# nrf7140_wificore register map
Vendor: Nordic Semiconductor; Series: nRF71; File version: 1
Registers are 32-bit, read-write, reset 0x0 unless marked. A register's access mark holds for its fields unless they carry their own. Offsets are from the block's base; [hi:lo] are bit positions; lines under a group give offsets from that group; {n}, {i} and the like mark numbered series.

## RPUPHY (part 3 of 8) — WIFICore RPU PHY peripherals
Base 0x48080000; alternate view of RPUMAC
0x8000 WLAN_CTRL group — Unspecified
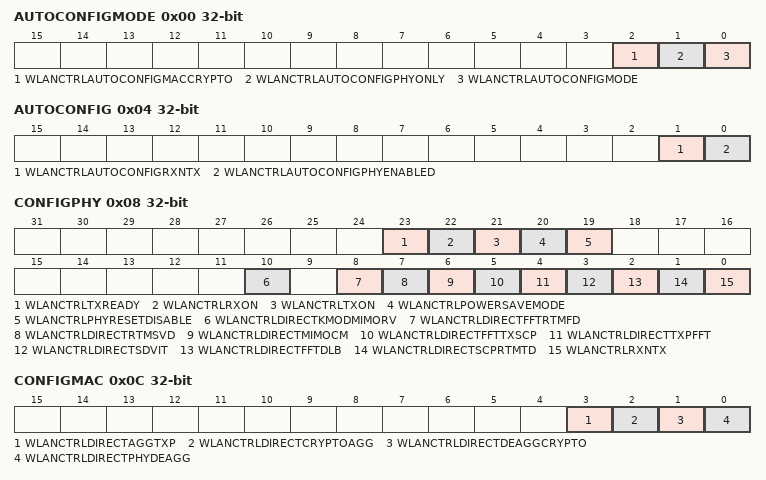
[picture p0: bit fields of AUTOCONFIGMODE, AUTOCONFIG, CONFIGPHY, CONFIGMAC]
  0x00 AUTOCONFIGMODE — WLAN CTRL AUTO CONFIG MODE
    [2] WLANCTRLAUTOCONFIGMACCRYPTO — Enable auto-configuration MAC with or without Crypto
      0=Auto-configure MAC pipeline with Crypto; 1=AutoConfigureMacPip1 (Auto-configure MAC pipeline without Crypto)
    [1] WLANCTRLAUTOCONFIGPHYONLY — Enable auto-configuration for PHY+MAC or PHY-only
      0=Auto-configure full PHY+MAC pipeline; 1=Auto-configure only PHY pipeline
    [0] WLANCTRLAUTOCONFIGMODE — Select mode used for automatic configuration:
      0=Automatic PHY configuration through WLAN_CTRL_AUTO_CONFIG register; 1=AutomaticPhyConfigur1 (Automatic PHY configuration using direct lines from MAC controller)
  0x04 AUTOCONFIG — WLAN CTRL AUTO CONFIG
    [1] WLANCTRLAUTOCONFIGRXNTX — Configure Wi-Fi RX or TX mode:
      0=Tx; 1=Rx
    [0] WLANCTRLAUTOCONFIGPHYENABLED — Enable PHY for either RX or TX:
      0=PhyDisabled; 1=PhyEnabled
  0x08 CONFIGPHY — WLAN CTRL CONFIG PHY
    [23] WLANCTRLTXREADY — Enable TX-SCP output:
      0=Disabled; 1=Enabled
    [22] WLANCTRLRXON — Set RF RX on:
      0=RxOff; 1=RxOn
    [21] WLANCTRLTXON — Set RF TX on:
      0=TxOff; 1=TxOn
    [20] WLANCTRLPOWERSAVEMODE — Enable Power Save mode:
      0=Disabled; 1=Enabled
    [19] WLANCTRLPHYRESETDISABLE — Control for automatic PHY reset (RX mode):
      0=PHY reset will be automatically generated; 1=No automatic PHY reset is generated
    [10] WLANCTRLDIRECTKMODMIMORV — Select whether MIMO RV input is from DMA channels or a direct connection between peripherals:
      0=DmaChannels; 1=Direct connection between peripherals
    [8] WLANCTRLDIRECTFFTRTMFD — Select whether FFT data input to RTM FD are from DMA channels or a direct connection from FFT:
      0=DmaChannels; 1=Direct connection between peripherals
    [7] WLANCTRLDIRECTRTMSVD — Select whether WLAN SVD input is from DMA channels or a direct connection between peripherals:
      0=DmaChannels; 1=Direct connection between peripherals
    [6] WLANCTRLDIRECTMIMOCM — Select whether MIMO Channel Matrix input is from DMA channels or a direct connection between peripherals:
      0=DmaChannels; 1=Direct connection between peripherals
    [5] WLANCTRLDIRECTFFTTXSCP — Select whether FFT output and TX-SCP input are to/from DMA channels or a direct connection between peripherals:
      0=DmaChannels; 1=Direct connection between peripherals
    [4] WLANCTRLDIRECTTXPFFT — Select whether TXP output and FFT input are to/from DMA channels or a direct connection between peripherals:
      0=DmaChannels; 1=Direct connection between peripherals
    [3] WLANCTRLDIRECTSDVIT — Select whether Stream Deparser outputs and Viterbi Decoder inputs are to/from DMA channels or a direct connection between peripherals:
      0=DmaChannels; 1=Direct connection between peripherals
    [2] WLANCTRLDIRECTFFTDLB — Select whether FFT output and DLB input are to/from DMA channels or a direct connection between peripherals:
      0=DmaChannels; 1=Direct connection between peripherals
    [1] WLANCTRLDIRECTSCPRTMTD — Select whether SCP outputs and RTM_TD input are to/from DMA channels or a direct connection between peripherals:
      0=DmaChannels; 1=Direct connection between peripherals
    [0] WLANCTRLRXNTX — Configure Wi-Fi RX or TX mode:
      0=Tx; 1=Rx
  0x0C CONFIGMAC — WLAN CTRL CONFIG MAC
    [all] fields
      0=DmaChannels; 1=Direct connection between peripherals
    [3] WLANCTRLDIRECTAGGTXP — Select whether Aggregation output and TXP input are to/from DMA channels or a direct connection between peripherals:
    [2] WLANCTRLDIRECTCRYPTOAGG — Select whether Crypto output and Aggregation input are to/from DMA channels or a direct connection between peripherals:
    [1] WLANCTRLDIRECTDEAGGCRYPTO — Select whether Deaggregation output and Crypto input are to/from DMA channels or a direct connection between peripherals:
    [0] WLANCTRLDIRECTPHYDEAGG — Select whether PHY outputs and Deaggregation inputs are to/from DMA channels or a direct connection between peripherals:
  0x10 TXHOLDOFF — WLAN CTRL TX HOLDOFF
    [13:0] WLANCTRLTXHOLDOFF — Specify TX hold-off to delay TX output to the DAC.Units are core clock cycles.
  0x14 TXEXTRAHOLDOFF — WLAN CTRL TX EXTRA HOLDOFF
    [13:0] WLANCTRLTXEXTRAHOLDOFF — Specify extra TX hold-off to delay TX output to the DAC.This extra hold-off can be selected through the TX vector.Units are core clock cycles.
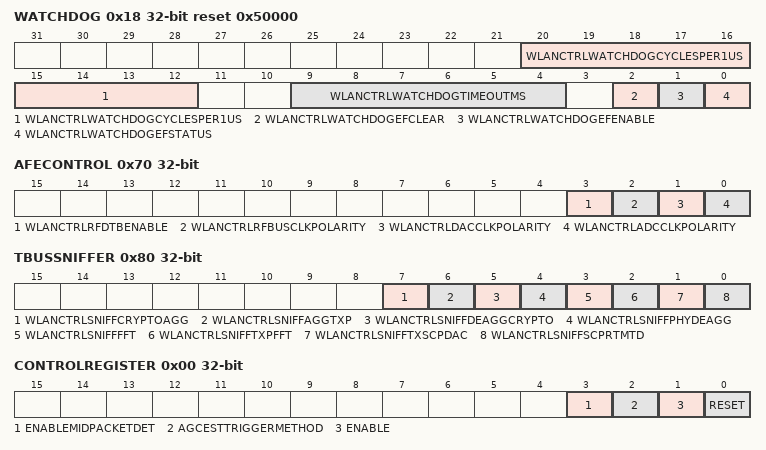
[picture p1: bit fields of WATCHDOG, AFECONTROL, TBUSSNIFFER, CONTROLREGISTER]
  0x18 WATCHDOG reset 0x50000 — WLAN CTRL WATCHDOG
    [20:12] WLANCTRLWATCHDOGCYCLESPER1US — Configure the number of core clock cycles per microsecond.
    [9:4] WLANCTRLWATCHDOGTIMEOUTMS — Specify watchdog timeout in milliseconds. Zero means the watchdog event flag is disabled.
    [2] WLANCTRLWATCHDOGEFCLEAR — WLAN watchdog event flag acknowledge/clear.Write 1 to clear WLAN_CTRL_WATCHDOG_EF_STATUS.Writing 0 has no effect.
    [1] WLANCTRLWATCHDOGEFENABLE — WLAN watchdog event flag enable.ANDed with WLAN_CTRL_WATCHDOG_EF_STATUS before generating EF output from block.
    [0] WLANCTRLWATCHDOGEFSTATUS — WLAN watchdog event flag status.Latched high when watchdog timer reaches programmed thresholdCan be forced high by writing 1 to this register for debug purposes (to test event flag connectivity in hardware and software).
  0x1C DEBUGPHYRESET ro — WLAN CTRL DEBUG PHY RESET
    [5:0] WLANCTRLDEBUGPHYRESET — Live state of the PHY reset signals0: PHY reset1: EDAGC reset2: SCP reset3: TD reset4: FD reset5: RXP reset
  0x20 DEBUGGING — WLAN CTRL DEBUG
    [1:0] WLANCTRLDEBUG — Enable debug registers PHY_VALID, PHY_ENABLE, MAC_VALID and MAC_ENABLE
      0=Disabled; 1=ValidEnable; 2=Sticky(Valid), Sticky(Enable); 3=Valid & Enable, Sticky(Valid & Enable)
  0x24 DEBUGPHYVALID ro — WLAN CTRL DEBUG PHY VALID
    [10:0] WLANCTRLDEBUGPHYVALID — Live state of the PHY valid flow control signals0: TXFD Input1: TXFD Output2: RXTD Input3: RXTD OFDM Output4: RXTD DSSS Output5: FFT Input6: FFT Output7: TXTD Input8: TXTD Output9: RXFD FFT Input10: RXFD Output
  0x28 DEBUGPHYENABLE ro — WLAN CTRL DEBUG PHY ENABLE
    [10:0] WLANCTRLDEBUGPHYENABLE — Live state of the PHY enable flow control signals0: TXFD Input1: TXFD Output2: RXTD Input3: RXTD OFDM Output4: RXTD DSSS Output5: FFT Input6: FFT Output7: TXTD Input8: TXTD Output9: RXFD FFT Input10: RXFD Output
  0x2C DEBUGMACVALID ro — WLAN CTRL DEBUG MAC VALID
    [6:0] WLANCTRLDEBUGMACVALID — Live state of the MAC valid flow control signals0: AGG WR1: AGG RD2: DEAGG WR3: DEAGG RD4: CRYPTO WR5: CRYPTO RD6: DECOMP WR
  0x30 DEBUGMACENABLE ro — WLAN CTRL DEBUG MAC ENABLE
    [6:0] WLANCTRLDEBUGMACENABLE — Live state of the MAC enable flow control signals0: AGG WR1: AGG RD2: DEAGG WR3: DEAGG RD4: CRYPTO WR5: CRYPTO RD6: DECOMP WR
  0x34 CCABUSYCOUNT0 — WLAN CTRL CCA BUSY COUNT 0
    [0] WLANCTRLCCABUSYCOUNTENA — Enable / disable CCA busy window counter. When disabled counter is set to zero.
  0x38 CCABUSYCOUNT1 ro — WLAN CTRL CCA BUSY COUNT 1
    [23:0] WLANCTRLCCABUSYCOUNTER — CCA busy window counter in Core clock cycles.
  0x3C NUMPAYLOADBYTESFORDEASSERTION — WLAN CTRL NUM PAYLOAD BYTES FOR DEASSERTION
    [5:0] WLANCTRLNUMPAYLOADBYTESFORDEASSERTION — Number of payload bytes after which PHY_RX_Request is deasserted.This value is set such that PHY-RX-Request is asserted till MAC hardware checkswhether MAC address of receiving packet is matching with expected address,i.e., this number should cover more than 10 bytes of MPDU.Typical value is 20 considering A-MPDU and some margin for MAC address matching.
  0x40 TMCOUNTERMSB — WLAN CTRL TM COUNTER MSB
    [23:0] WLANCTRLTMCOUNTERMSB — MSB of Counter used for time measurement snapshots
  0x44 TMCOUNTERLSB — WLAN CTRL TM COUNTER LSB
    [23:0] WLANCTRLTMCOUNTERLSB — LSB of Counter used for time measurement snapshots
  0x48 ADCFIRSTSAMPLESNAPSHOTMSB ro — WLAN CTRL ADC FIRST SAMPLE SNAPSHOT MSB
    [23:0] WLANCTRLADCFIRSTSAMPLESNAPSHOTMSB — MSB of snapshot of time measurement counter, taken when first sample of ADC goes valid
  0x4C ADCFIRSTSAMPLESNAPSHOTLSB ro — WLAN CTRL ADC FIRST SAMPLE SNAPSHOT LSB
    [23:0] WLANCTRLADCFIRSTSAMPLESNAPSHOTLSB — LSB of snapshot of time measurement counter, taken when first sample of ADC goes valid
  0x50 TMCOUNTERCTRL — WLAN CTRL TM COUNTER CTRL
    [0] WLANCTRLTMCOUNTERENABLE — Enable signal for 48-bit time measurement counter
  0x54 TXABORTCONTROL — WLAN CTRL TX ABORT CONTROL
    [0] WLANCTRLTXABORTCONTROL — Control to assert wlan_ctrl_rx_on when TX_ABORT is received.
      0=Do not assert wlan_ctrl_rx_on; 1=Assert wlan_ctrl_rx_on when abort_status is high
  0x58 OFDMRTMSCPEOPSNAPSHOTMSB ro — WLAN CTRL OFDM RTM SCP EOP SNAPSHOT MSB
    [23:0] WLANCTRLOFDMRTMSCPEOPSNAPSHOTMSB — MSB of snapshot of time measurement counter, taken when OFDM Receiver Training Mode - SCP EOP goes high
  0x5C OFDMRTMSCPEOPSNAPSHOTLSB ro — WLAN CTRL OFDM RTM SCP EOP SNAPSHOT LSB
    [23:0] WLANCTRLOFDMRTMSCPEOPSNAPSHOTLSB — LSB of snapshot of time measurement counter, taken when OFDM Receiver Training Mode - SCP EOP goes high
  0x60 OFDMRTMFDEOPSNAPSHOTMSB ro — WLAN CTRL OFDM RTM FD EOP SNAPSHOT MSB
    [23:0] WLANCTRLOFDMRTMFDEOPSNAPSHOTMSB — MSB of snapshot of time measurement counter, taken when OFDM Receiver Training Mode - FD EOP goes high
  0x64 OFDMRTMFDEOPSNAPSHOTLSB ro — WLAN CTRL OFDM RTM FD EOP SNAPSHOT LSB
    [23:0] WLANCTRLOFDMRTMFDEOPSNAPSHOTLSB — LSB of snapshot of time measurement counter, taken when OFDM Receiver Training Mode - FD EOP goes high
  0x68 TMCOUNTERSNAPSHOTMSB — WLAN CTRL TM COUNTER SNAPSHOT MSB
    [23:0] WLANCTRLTMCOUNTERSNAPSHOTMSB — MSB of snapshot of time measurement counter, taken when either WLAN_CTRL_TM_COUNTER_SNAPSHOT_MSB or WLAN_CTRL_TM_COUNTER_SNAPSHOT_LSB is written
  0x6C TMCOUNTERSNAPSHOTLSB — WLAN CTRL TM COUNTER SNAPSHOT LSB
    [23:0] WLANCTRLTMCOUNTERSNAPSHOTLSB — LSB of snapshot of time measurement counter, taken when either WLAN_CTRL_TM_COUNTER_SNAPSHOT_MSB or WLAN_CTRL_TM_COUNTER_SNAPSHOT_LSB is written
  0x70 AFECONTROL — WLAN CTRL AFE CONTROL
    [3] WLANCTRLRFDTBENABLE — RF Digital Test Bus enable
      0=RfDtbNotEnabled; 1=RfDrbEnabled
    [2] WLANCTRLRFBUSCLKPOLARITY — RF bus clock polarity:
      0=PositiveEdge; 1=NegativeEdge
    [1] WLANCTRLDACCLKPOLARITY — DAC sample clock polarity:
      0=PositiveEdge; 1=NegativeEdge
    [0] WLANCTRLADCCLKPOLARITY — ADC sample clock polarity:
      0=PositiveEdge; 1=NegativeEdge
  0x74 RFPMUUP — WLAN CTRL RF PMU UP
    [0] WLANCTRLRFPMUUP — Enable RF:
      0=Not enabled (PMU_UP_P=0 and PMU_UP_N=1); 1=Enabled (PMU_UP_P=1 and PMU_UP_N=0)
  0x78 RFBANDSEL — WLAN CTRL RF BAND SEL
    [0] WLANCTRLRFBANDSEL — Select between low band and high band RF:
      0=LowBand; 1=HighBand
  0x80 TBUSSNIFFER — WLAN CTRL TBUS SNIFFER
    [all] fields
      0=NotSniffed; 1=Sniff Tbus connection whilst in direct connection
    [7] WLANCTRLSNIFFCRYPTOAGG — Select whether Crypto outputs and Agg input are output to the EDC during direct connection:
    [6] WLANCTRLSNIFFAGGTXP — Select whether AGG outputs and TXP input are output to the EDC during direct connection:
    [5] WLANCTRLSNIFFDEAGGCRYPTO — Select whether DEAGG outputs and CRYPTO input are output to the EDC during direct connection:
    [4] WLANCTRLSNIFFPHYDEAGG — Select whether PHY outputs and DEAGG input are output to the EDC during direct connection:
    [3] WLANCTRLSNIFFFFT — Select whether FFT outputs and MIMO/TXSCP input are output to the EDC during direct connection:
    [2] WLANCTRLSNIFFTXPFFT — Select whether TXP outputs and FFT input are output to the EDC during direct connection:
    [1] WLANCTRLSNIFFTXSCPDAC — Select whether TX-SCP outputs and DAC input are output to the EDC during direct connection:
    [0] WLANCTRLSNIFFSCPRTMTD — Select whether SCP outputs and RTM_TD input are output to the EDC during direct connection:
  0xFC WLANCOREREVISION ro
    [23:0] WLANCOREREVISION — WiFi Core revision : Major(8).Minor(8).Maintenance(8)
0x9000 WLAN_ED group — Unspecified
  0x00 CONTROLREGISTER — WLAN ED CONTROL REGISTER
    [3] ENABLEMIDPACKETDET — When set Mid-Packet detection is enabled; otherwise only DSSS and OFDM packets will be detected.
    [2] AGCESTTRIGGERMETHOD — Defines the AGC trigger method.'0' -Agc estimation process starts only after ED done'1' -Agc is free running and starts adjusting gain value if absolute difference in RSSI and target value is more than threshold.
    [1] ENABLE — 1: Enables ED module0: Disables ED module
    [0] RESET — 1: Asserts reset0: De-asserts reset
  0x04 WAITCOUNTER — WLAN ED WAIT COUNTER
    [7:0] WAITCOUNT — Number of data samples for which module waits before it actually starts processing.
  0x08 THRESHSETTINGS — WLAN ED THRESH SETTINGS
    [7:0] EDTHRESHOLD — RSSI Threshold in dBm corresponding to sensitivity required. Signal crossing this threshold indicates energy in the channel.
  0x0C ESTIMATIONLENGTH — WLAN ED ESTIMATION LENGTH
    [1:0] ESTIMATIONLENGTH — No of symbols to be averaged to Estimate Average variance.0: 1 symbol, 1: 2 symbols, 2: 4 symbols, 3: 8 symbols
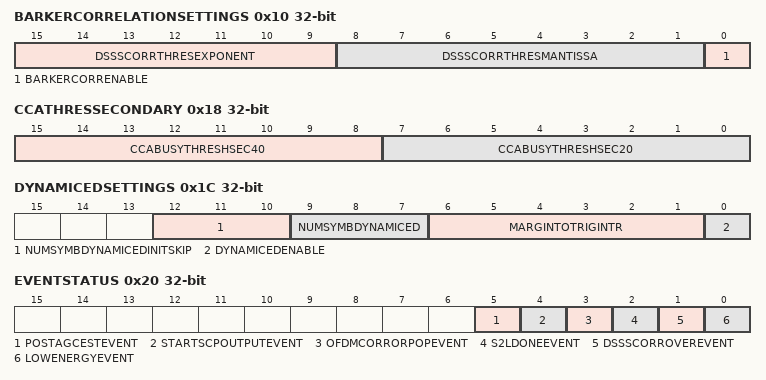
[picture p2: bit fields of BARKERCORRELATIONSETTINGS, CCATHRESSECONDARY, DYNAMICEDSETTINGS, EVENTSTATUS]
  0x10 BARKERCORRELATIONSETTINGS — WLAN ED BARKER CORRELATION SETTINGS
    [15:9] DSSSCORRTHRESEXPONENT — DSSS Correlation Threshold:Represents 8 bit Exponent value of Threshold.
    [8:1] DSSSCORRTHRESMANTISSA — DSSS Correlation Threshold:Represents 8 bit Mantissa value of Threshold.
    [0] BARKERCORRENABLE — 1: Enables Barker correlationThis correlation is performed on data stream-1.
  0x14 CCATHRESPRIM20 — WLAN ED CCA THRES PRIM20
    [7:0] CCABUSYTHRESHPRIM20 — Signal level in dB corresponding to CCA threshold in the primary 20MHz channel. The threshold is given in 2's complement form.
  0x18 CCATHRESSECONDARY — WLAN ED CCA THRES SECONDARY
    [15:8] CCABUSYTHRESHSEC40 — Signal level in dB corresponding to CCA threshold in the secondary 40MHz channel. The threshold is given in 2's complement form.
    [7:0] CCABUSYTHRESHSEC20 — Signal level in dB corresponding to CCA threshold in the secondary 20MHz channel. The threshold is given in 2's complement form.
  0x1C DYNAMICEDSETTINGS — WLAN ED DYNAMIC ED SETTINGS
    [12:10] NUMSYMBDYNAMICEDINITSKIP — This specifies the number of consecutive below-threshold events to skip, before starting the count for low energy event. Can take values from 0 to 7. Suppose the value is 3 then it skips first 3 consecutive below-threshold symbols, then proceeds to count for generating low energy event. If the below-threshold events are not consecutive then the count is reset.
    [9:7] NUMSYMBDYNAMICED — Number of Symbols to determine Average Energy. Valid only when Dynamic ED is enabled.0: 1 symbol, 1: 2 symbols, 2: 4 symbols, 3: 8 symbols, 4:16 symbols, 5: 32 symbols, 6: 64 symbols, 7: 128 symbols
    [6:1] MARGINTOTRIGINTR — If the energy found over all the NUM_SYMB_DYNAMIC_ED symbols is consistently below the ED threshold an interrupt is generated. Field is valid only when dynamic ED is enabled. 0: 0dB, 1: 1dB, 2: 2 dB15: 15 dB.
    [0] DYNAMICEDENABLE — 1-Enable, 0-Disable
  0x20 EVENTSTATUS ro — WLAN ED EVENT STATUS
    [5] POSTAGCESTEVENT — This event register holds the status of the post AGC estimations being valid.'1' - Event detected.'0' - Event not detected.
    [4] STARTSCPOUTPUTEVENT — This event register holds the status of the SCP output and indicates when the SCP output was set valid.'1' - Event detected.'0' - Event not detected.
    [3] OFDMCORRORPOPEVENT — This event status register holds the status of post AGC OFDM correlation completion if AGC_EST_TRIGGER_METHOD is 0 or packet over packet detection event if AGC_EST_TRIGGER_METHOD is 1.'1' - Event detected.'0' - Event not detected.
    [2] S2LDONEEVENT — '1' - S2L processing is over.'0' - S2L processing is not over.
    [1] DSSSCORROVEREVENT — This field will be set once the correlation is done over desired number of symbols after assertion of AGC done signal.
    [0] LOWENERGYEVENT — 1: Event status. Asserted when energy is below a threshold by a margin
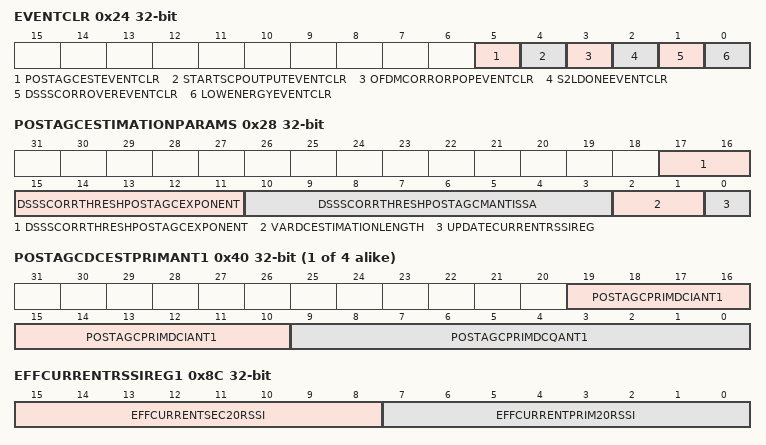
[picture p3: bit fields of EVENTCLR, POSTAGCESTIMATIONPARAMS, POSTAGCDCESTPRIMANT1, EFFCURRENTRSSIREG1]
  0x24 EVENTCLR — WLAN ED EVENT CLR
    [5] POSTAGCESTEVENTCLR — This event clear register resets the status of the post AGC estimations.
    [4] STARTSCPOUTPUTEVENTCLR — This event clear register resets the status of the SCP output event.
    [3] OFDMCORRORPOPEVENTCLR — This event clear register resets the status of post AGC OFDM correlation completion or packet over packet detection event.
    [2] S2LDONEEVENTCLR — Clears the S2L done Event.
    [1] DSSSCORROVEREVENTCLR — Clears DSSS correlation event
    [0] LOWENERGYEVENTCLR — Clears low energy event
  0x28 POSTAGCESTIMATIONPARAMS — WLAN ED POST AGC ESTIMATION PARAMS
    [17:11] DSSSCORRTHRESHPOSTAGCEXPONENT — DSSS Correlation Threshold:Represents 8 bit Exponent value of Threshold.
    [10:3] DSSSCORRTHRESHPOSTAGCMANTISSA — DSSS Correlation Threshold:Represents 8 bit Mantissa value of Threshold.
    [2:1] VARDCESTIMATIONLENGTH — Number of symbol over which variance is computed after AGC estimation.0: 1 symbol1: 2 symbols2: 4 symbols3: 8 symbolsEach symbol constitutes number of samples defined in estimation length (ESTIMATION_LENGTH_1)
    [0] UPDATECURRENTRSSIREG — Flag to Enable or Disable, update of RSSI register values with Current Symbol RSSI
  {0x14+0x18*j} POSTAGCVARIANCEESTPRIM80ANT{j} ro (j=1..4) — WLAN ED POSTAGC VARIANCE EST PRIM80 ANT{j}
    [19:0] POSTAGCPRIM80VARANT{j} — Post AGC variance average of primary 80MHz channel for antenna {j}
  {0x18+0x18*j} POSTAGCVARIANCEESTPRIM40ANT{j} ro (j=1..4) — WLAN ED POSTAGC VARIANCE EST PRIM40 ANT{j}
    [19:0] POSTAGCPRIM40VARANT{j} — Post AGC variance average of primary 40MHz channel for antenna {j}
  {0x1C+0x18*j} POSTAGCVARIANCEESTPRIM20ANT{j} ro (j=1..4) — WLAN ED POSTAGC VARIANCE EST PRIM20 ANT{j}
    [19:0] POSTAGCPRIM20VARANT{j} — Post AGC variance average of primary 20MHz channel for antenna {j}
  {0x20+0x18*j} POSTAGCVARIANCEESTSEC40ANT{j} ro (j=1..4) — WLAN ED POSTAGC VARIANCE EST SEC40 ANT{j}
    [19:0] POSTAGCSEC40VARANT{j} — Post AGC variance average of secondary 40MHz channel for antenna {j}
  {0x24+0x18*j} POSTAGCVARIANCEESTSEC20ANT{j} ro (j=1..4) — WLAN ED POSTAGC VARIANCE EST SEC20 ANT{j}
    [19:0] POSTAGCSEC20VARANT{j} — Post AGC variance average of secondary 20MHz channel for antenna {j}
  {0x28+0x18*j} POSTAGCDCESTPRIMANT{j} ro (j=1..4) — WLAN ED POSTAGC DCEST PRIM ANT{j}
    [19:10] POSTAGCPRIMDCIANT{j} — DC offset of I component of primary input stream after AGC estimation is completed for antenna {j}. If RX_OPER_FS is:00 then primary input implies primary 20MHz channel01 then primary input implies primary 40MHz channel10 then primary input implies primary 80MHz channel
    [9:0] POSTAGCPRIMDCQANT{j} — DC offset of Q component of primary input stream after AGC estimation is completed for antenna {j}. If RX_OPER_FS is:00 then primary input implies primary 20MHz channel01 then primary input implies primary 40MHz channel10 then primary input implies primary 80MHz channel
  0x8C EFFCURRENTRSSIREG1 ro — WLAN ED EFF CURRENT RSSI REG1
    [15:8] EFFCURRENTSEC20RSSI — Effective current symbol secondary 20MHz RSSI
    [7:0] EFFCURRENTPRIM20RSSI — Effective current symbol primary 20MHz RSSI.
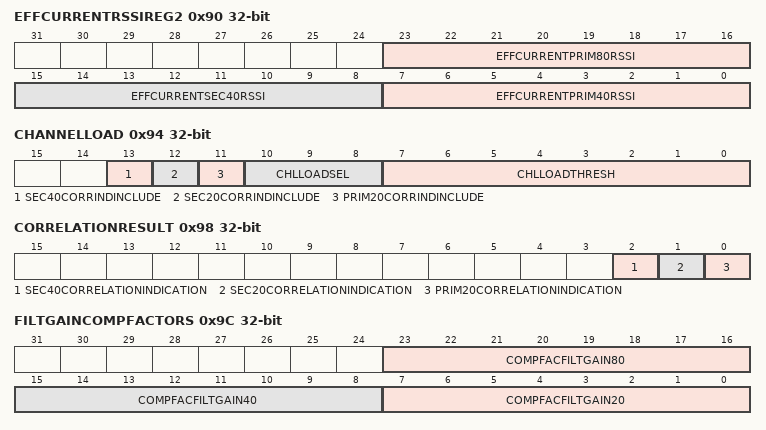
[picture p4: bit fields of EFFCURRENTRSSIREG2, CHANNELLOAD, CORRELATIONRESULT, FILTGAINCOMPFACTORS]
  0x90 EFFCURRENTRSSIREG2 ro — WLAN ED EFF CURRENT RSSI REG2
    [23:16] EFFCURRENTPRIM80RSSI — Effective current symbol primary 80MHz RSSI.
    [15:8] EFFCURRENTSEC40RSSI — Effective current symbol secondary 40MHz RSSI.
    [7:0] EFFCURRENTPRIM40RSSI — Effective current symbol primary 40MHz RSSI.
  0x94 CHANNELLOAD — WLAN ED CHANNEL LOAD
    [13] SEC40CORRINDINCLUDE — If this is set secondary40 correlation result in included in providing channel load information.
    [12] SEC20CORRINDINCLUDE — If this is set secondary20 correlation result in included in providing channel load information.
    [11] PRIM20CORRINDINCLUDE — If this is set primary correlation result in included in providing channel load information.
    [10:8] CHLLOADSEL — 012
    [7:0] CHLLOADTHRESH — A signal is asserted whenever received signal in primary channel crossing this threshold . Threshold value is configured in steps of 1dB ranging from -128dB to 127dB.
  0x98 CORRELATIONRESULT — WLAN ED CORRELATION RESULT
    [2] SEC40CORRELATIONINDICATION — This signal logical 'OR'ed with CCA busy of secondary 40MHz channel indicates channel busy condition. This can be cleared once PLCP header is successfully received.MCP sets this bit if it sees correlation successful in secondary 40MHz channel.
    [1] SEC20CORRELATIONINDICATION — This signal logical 'OR'ed with CCA busy of secondary 20MHz channel indicates channel busy condition. This can be cleared once PLCP header is successfully received.MCP sets this bit if it sees correlation successful in secondary channel.
    [0] PRIM20CORRELATIONINDICATION — This signal logical 'OR'ed with CCA busy of primary 20MHz channel indicates channel busy condition. This can be cleared once PLCP header is successfully received. MCP sets this bit if it sees correlation successful in secondary channel.
  0x9C FILTGAINCOMPFACTORS — WLAN ED FILT GAIN COMP FACTORS
    [23:16] COMPFACFILTGAIN80 — This is gain difference between two filters.Value = 20**log10(2^(N_ADC_BITS-1)/ADC_PK_VOLT) + (FILT1_GAIN - FILT2_GAIN)N_ADC_BITS : Number of ADC bits (10)ADC_PK_VOLT : ADC peak voltage level (0.5V)FILT_GAIN: Gain in dB due to filter
    [15:8] COMPFACFILTGAIN40 — Value = 20**log10(2^(N_ADC_BITS-1)/ADC_PK_VOLT) + FILT_GAINN_ADC_BITS : Number of ADC bits (10)ADC_PK_VOLT : ADC peak voltage level (0.5V)FILT_GAIN: Gain in dB due to filter
    [7:0] COMPFACFILTGAIN20 — Value = 20**log10(2^(N_ADC_BITS-1)/ADC_PK_VOLT) + FILT_GAINN_ADC_BITS : Number of ADC bits (10)ADC_PK_VOLT : ADC peak voltage level (0.5V)FILT_GAIN: Gain in dB due to filter
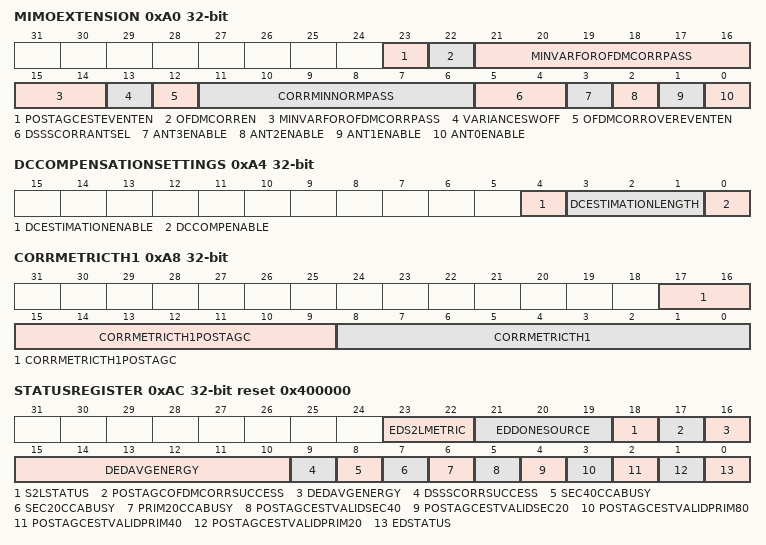
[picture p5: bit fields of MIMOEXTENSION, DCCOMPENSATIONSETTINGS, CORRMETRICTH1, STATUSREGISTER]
  0xA0 MIMOEXTENSION — WLAN ED MIMO EXTENSION
    [23] POSTAGCESTEVENTEN — This register enables the assertion of post AGC estimation event.'0' - Event assertion is disabled.'1' - Event assertion is enabled.
    [22] OFDMCORREN — OFDM correlation enable.'1' - OFDM correlation enabled.'0' - OFDM correlation disabled.
    [21:14] MINVARFOROFDMCORRPASS — This register holds the minimum value of RSSI in dBm (signed), that is necessary for OFDM correlation check to pass. If the computed RSSI is below thisvalue then even though OFDM correlation metric is high the OFDM correlation success will not be enabled, so ED will not be successful. This is used for preventing low amplitude periodic signals especially DC offset from triggering OFDM correlation based ED.
    [13] VARIANCESWOFF — Bit to switch off the variance computation modules inside ed module.'1' - switch off the variance estimation modules.'0' - don't switch off. Controlled according to internal logic.
    [12] OFDMCORROVEREVENTEN — This register enable the assertion of OFDM post AGC correlation done event.'0' - Event assertion is disabled.'1' - Enabled.
    [11:6] CORRMINNORMPASS — Denotes the number of passes for the correlation metric above threshold for Correlation Pass in ED.
    [5:4] DSSSCORRANTSEL — The antenna index to be selected for DSSS correlation in ED. Can be from 0 to 3.
    [3] ANT3ENABLE — Enables Antenna 3 input processing in ED module
    [2] ANT2ENABLE — Enables Antenna 2 input processing in ED module
    [1] ANT1ENABLE — Enables Antenna 1 input processing in ED module
    [0] ANT0ENABLE — Enables Antenna 0 input processing for ED module.
  0xA4 DCCOMPENSATIONSETTINGS — WLAN ED DC COMPENSATION SETTINGS
    [4] DCESTIMATIONENABLE
    [3:1] DCESTIMATIONLENGTH — DC Estimation Length indicates the number of samples over which DC should be estimated in the signal preprocessor block.'000' - 8 Samples'001' - 16 Samples'010' - 32 Samples'011' - 64 Samples'100' - 128 Samples
    [0] DCCOMPENABLE — 1->Enable DC compensation0->Disable DC compensation
  0xA8 CORRMETRICTH1 — WLAN ED CORR METRIC TH1
    [17:9] CORRMETRICTH1POSTAGC — Post AGC CorrMetric Threshold.Contains two's complement representation of corr metric threshold , in dB with 3 bit precision after decimal point. i.e. upto 0.125dB accuracy. For example, 332 indicates -22.5dB threshold. 257 indicates -31.875dB threshold.
    [8:0] CORRMETRICTH1 — Contains two's complement representation of corr metric threshold , in dB with 3 bit precision after decimal point. i.e. upto 0.125dB accuracy. For example, 332 indicates -22.5dB threshold. 257 indicates -31.875dB threshold.
  0xAC STATUSREGISTER ro reset 0x400000 — WLAN ED STATUS REGISTER
    [23:22] EDS2LMETRIC — This register indicates the metric of s2l done event.
    [21:19] EDDONESOURCE — This register indicates the source of ED done event.'001' - ED due to prim20 variance exceeding threshold.'010' - ED due to prim20 OFDM correlation exceeding threshold.'011' - ED due to prim20 DSSS correlation exceeding threshold.'100' - ED due to prim20 RSSI between ED detection and CCA'101' - ED due to sec20 RSSI between ED detection and CCA'110' - ED due to sec40 RSSI between ED detection and CCAThe value in this register is only valid when ED_STATUS=1.When ED_STATUS=0 the value in this register is only for debug purposes.
    [18] S2LSTATUS — '1' - S2L Detected.'0' - S2L TimeOut.
    [17] POSTAGCOFDMCORRSUCCESS — This bit gives the post AGC OFDM correlation status.'0' - Correlation Failure.'1' - Correlation success.
    [16:10] DEDAVGENERGY — This is the estimate of average energy in dB (10**log10(var)) when dynamic ed event occured
    [9] DSSSCORRSUCCESS — Value of '1' indicates DSSS correlation is successful.
    [8] SEC40CCABUSY — Level 'High' indicates secondary channel is busy.
    [7] SEC20CCABUSY — Secondary 20MHz CCA Busy Signal.
    [6] PRIM20CCABUSY — Primary20MHz CCA Busy Signal
    [5] POSTAGCESTVALIDSEC40 — Value '1' indicates post AGC estimation performed over sec40 signal are valid.
    [4] POSTAGCESTVALIDSEC20 — Value '1' indicates post AGC estimation performed over sec20 signal are valid.
    [3] POSTAGCESTVALIDPRIM80 — Value '1' indicates post AGC estimation performed over prim80 signal are valid.
    [2] POSTAGCESTVALIDPRIM40 — Value '1' indicates post AGC estimation performed over prim40 signal are valid.
    [1] POSTAGCESTVALIDPRIM20 — Value '1' indicates post AGC estimation performed over prim20 signal are valid.
    [0] EDSTATUS — Level 'High' indicates energy is detected.
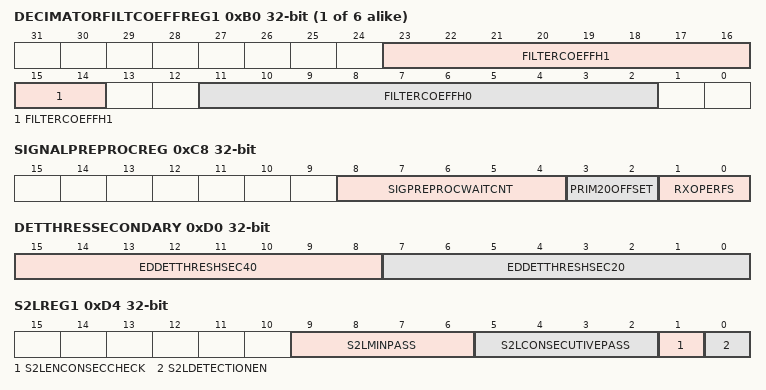
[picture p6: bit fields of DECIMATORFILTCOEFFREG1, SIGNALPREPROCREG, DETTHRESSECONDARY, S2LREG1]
  {0xAC+4j} DECIMATORFILTCOEFFREG{j} (j=1..6) — WLAN ED DECIMATOR FILT COEFF REG{j}
    [23:14] FILTERCOEFFH{2j-1} — Decimator filter tap {2j-1} coefficients. Expressed in 10-bit 2's complement
    [11:2] FILTERCOEFFH{2j-2} — Decimator filter tap {2j-2} coefficients. Expressed in 10-bit 2's complement
  0xC8 SIGNALPREPROCREG — WLAN ED SIGNAL PREPROC REG
    [8:4] SIGPREPROCWAITCNT — This is a 5-bit value specifies how many valid scp output samples to wait before enabling the signal preprocessor
    [3:2] PRIM20OFFSET — This indicates the offset of the primary20MHz.if RX_OPER_FS = '00' (20MHz)'00' - This is the only allowed value.if RX_OPER_FS = '01' (40MHz)'00' - Primary 20 is the lower 20 MHz.'01' - Primary 20 is the upper 20 MHz.if RX_OPER_FS = '02' (80MHz)'00' - Primary 20 is the lower 20 MHz of the lower 40MHz.'01' - Primary 20 is the upper 20 MHz of the lower 40MHz.'10' - Primary 20 is the lower 20 MHz of the upper 40MHz.'11' - Primary 20 is the upper 20 MHz of the upper 40MHz.
    [1:0] RXOPERFS — This indicates the Fs at which the RX is operating
      0=RxAt20Mhz; 1=RxAt40Mhz; 2=RxAt80Mhz
  0xCC DETTHRESPRIM20 — WLAN ED DET THRES PRIM20
    [7:0] EDDETTHRESHPRIM20 — Signal level in dB corresponding to ED Detected threshold in the primary 20MHz channel. ED done will be given if primary 20 RSSI is greater than this threshold and less than prim20 CCA busy threshold. The threshold is given in 2's complement form.
  0xD0 DETTHRESSECONDARY — WLAN ED DET THRES SECONDARY
    [15:8] EDDETTHRESHSEC40 — Signal level in dB corresponding to ED Detected threshold in the secondary 40MHz channel. ED done will be given if secondary 40 RSSI is greater than this threshold and less than sec40 CCA busy threshold. The threshold is given in 2's complement form.
    [7:0] EDDETTHRESHSEC20 — Signal level in dB corresponding to ED Detected threshold in the secondary 20MHz channel. ED done will be given if secondary 20 RSSI is greater than this threshold and less than sec20 CCA busy threshold. The threshold is given in 2's complement form.
  0xD4 S2LREG1 — WLAN ED S2L REG1
    [9:6] S2LMINPASS — Denotes the min number of times the OFDM corr metric should be below the S2L threshold, for S2L detection to happen.
    [5:2] S2LCONSECUTIVEPASS — Denotes the consecutive number of times the OFDM correlation metric be below the S2L detection threshold, so as to indicate S2L detected.
    [1] S2LENCONSECCHECK — '1' - Enables consecutives passes check for S2L detection.'0' - enables minimum pass check for S2L detection.
    [0] S2LDETECTIONEN — '1' - S2L detection in ED module is enabled.'0' - disabled
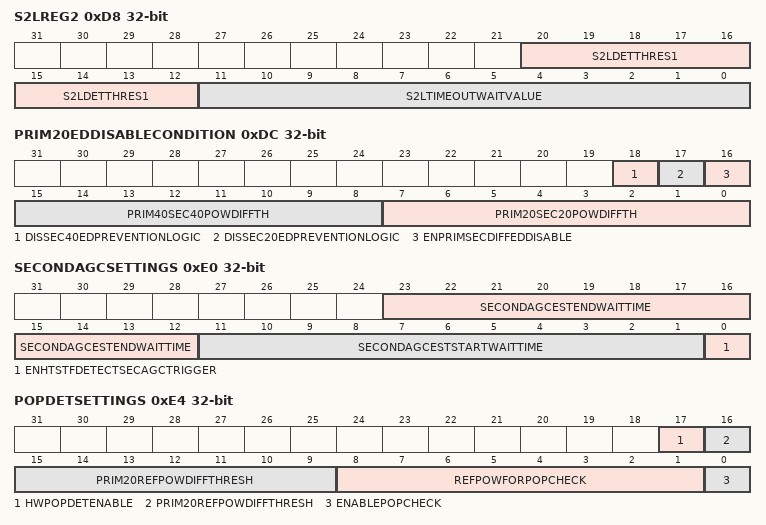
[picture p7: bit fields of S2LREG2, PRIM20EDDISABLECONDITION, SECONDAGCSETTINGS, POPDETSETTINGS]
  0xD8 S2LREG2 — WLAN ED S2L REG2
    [20:12] S2LDETTHRES1 — Contains two's complement representation of S2L corr metric threshold , in dB with 3 bit precision after decimal point. i.e. upto 0.125dB accuracy. For example, 332 indicates -22.5dB threshold. 257 indicates -31.875dB threshold.
    [11:0] S2LTIMEOUTWAITVALUE — This is the number of 20MHz starting from AGC done, that we need to wait before asserting Timeout Event incase S2L detection does not happen. If S2L detection event is generated, then S2L timeout event will not be generated.
  0xDC PRIM20EDDISABLECONDITION — WLAN ED PRIM20 ED DISABLE CONDITION
    [18] DISSEC40EDPREVENTIONLOGIC — Sec40 ED detection Prevention Logic.Prevent Sec40 ED (ED Source = 6) from getting asserted if we determine that it is caused by leakage from either Prim20 or Sec20 band.'1' - Disables the logic.'0' - Enables the logic.
    [17] DISSEC20EDPREVENTIONLOGIC — Sec20 ED detection Prevention Logic.Prevent Sec20 ED (ED Source = 5) from getting asserted if we determine that it is caused by leakage from either Prim20 or Sec40 band.'1' - Disables the logic.'0' - Enables the logic.
    [16] ENPRIMSECDIFFEDDISABLE — '1' - Enables the logic which prevents the ED in primary 20MHz from triggering if secRSSI-primRSSI > threshold.'0' - Disables.
    [15:8] PRIM40SEC40POWDIFFTH — This parameter gives th 8-bit difference in RSSI between primary 40 and secondary 40 above which primary20 ED Status is disabled.
    [7:0] PRIM20SEC20POWDIFFTH — This parameter gives th 8-bit difference in RSSI between primary 20 and secondary 20 above which primary20 ED Status is disabled.
  0xE0 SECONDAGCSETTINGS — WLAN ED SECOND AGC SETTINGS
    [23:12] SECONDAGCESTENDWAITTIME — Contains the time out value upto which will wait from s2l point and stops the HT-STF detection if it is not detected.NOTE: A value of zero disables the check to stop the detection.
    [11:1] SECONDAGCESTSTARTWAITTIME — Contains the time out value upto which, will wait from s2l point and triggers second AGC process immediately or after HT-STF detection depends on the flag.NOTE: A value of zero disables the trigger.
    [0] ENHTSTFDETECTSECAGCTRIGGER — The Second Agc Estimation process trigger will depend on the HT-STF detection if this flag is enabled,otherwise it will depend on the time out from the s2l point.
  0xE4 POPDETSETTINGS — WLAN ED POP DET SETTINGS
    [17] HWPOPDETENABLE — Enabling POP directly from hardware through this bit. When this bit is set, PoP logic is automatically enabled after ED detection. RSSI estimated in ED module is used as base RSSI for PoP.When this bit is not set then PoP logic depends on ENABLE_POP_CHECK field.
    [16:9] PRIM20REFPOWDIFFTHRESH — This parameter gives the threshold value for difference in RSSI between primary 20MHz and reference above which packet over oacket detecetion event is set.
    [8:1] REFPOWFORPOPCHECK — This is a two's complement value which is the reference power for packet over packet detection. This is set by MCP with the primary 20MHz RSSI of present decoding packet.
    [0] ENABLEPOPCHECK — Enables or disables packet over packet detection:'1' - Enable packet over packet detection.'0' - Disable packet over packet detection.Before setting this bit, make sure REF_POW_FOR_POP_CHECK and PRIM20_REF_POW_DIFF_THRESH are configured appropriately.
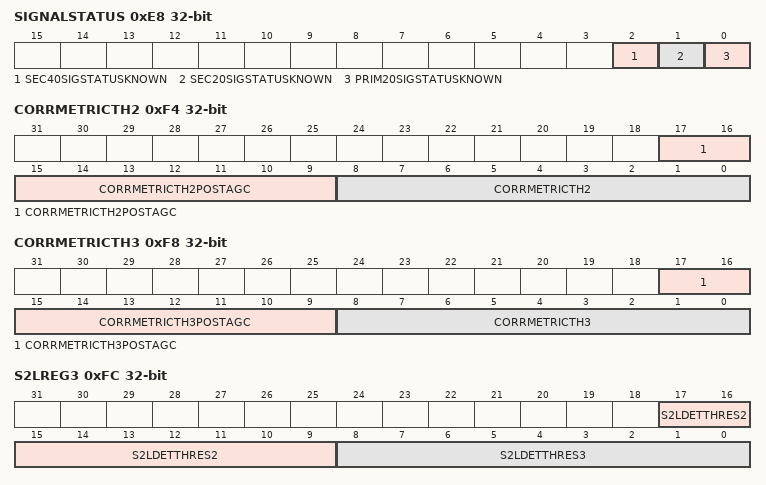
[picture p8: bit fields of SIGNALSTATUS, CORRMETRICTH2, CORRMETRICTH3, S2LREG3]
  0xE8 SIGNALSTATUS — WLAN ED SIGNAL STATUS
    [2] SEC40SIGSTATUSKNOWN — This register disables ED detection due to secondary 40MHz RSSI. This is set to '1' by MCP during Mid-packet detection.
    [1] SEC20SIGSTATUSKNOWN — This register disables ED detection due to secondary 20MHz RSSI. This is set to '1' by MCP during Mid-packet detection.
    [0] PRIM20SIGSTATUSKNOWN — This register disables ED detection due to primary 20MHz RSSI. This is set to '1' by MCP during Mid-packet detection.
  0xEC CORRSUCCESSWAITTIME — WLAN ED CORR SUCCESS WAIT TIME
    [9:0] PRIM20CORRSUCCESSTIMEOUTWAITVALUE — Contains the timeout wait value for the primary 20MHz samples after which the correlation success wait done flag is set to 1 to allow OFDM or DSSS correlation success to happen before triggering ED done. The counter starts incrementing when estimated primary 20MHz RSSI becomes greater than ED detection threshold and less than CCA busy threshold.
  0xF0 ENAGCTRANSIENTEDRESET — WLAN ED EN AGC TRANSIENT ED RESET
    [0] ENAGCTRANSIENTEDRESET — Defines the ED reset behaviour when AGC is in transient.'1' - Allows the Agc in transient flag based ED reset before ED_STATUS is asserted.'0' - Allows the Agc in transient flag based ED reset irrespective of ED_STATUS.
  0xF4 CORRMETRICTH2 — WLAN ED CORR METRIC TH2
    [17:9] CORRMETRICTH2POSTAGC — Post AGC CorrMetric Threshold.Contains two's complement representation of corr metric threshold , in dB with 3 bit precision after decimal point. i.e. upto 0.125dB accuracy. For example, 332 indicates -22.5dB threshold. 257 indicates -31.875dB threshold.
    [8:0] CORRMETRICTH2 — Contains two's complement representation of corr metric threshold , in dB with 3 bit precision after decimal point. i.e. upto 0.125dB accuracy. For example, 332 indicates -22.5dB threshold. 257 indicates -31.875dB threshold.
  0xF8 CORRMETRICTH3 — WLAN ED CORR METRIC TH3
    [17:9] CORRMETRICTH3POSTAGC — Post AGC CorrMetric Threshold.Contains two's complement representation of corr metric threshold , in dB with 3 bit precision after decimal point. i.e. upto 0.125dB accuracy. For example, 332 indicates -22.5dB threshold. 257 indicates -31.875dB threshold.
    [8:0] CORRMETRICTH3 — Contains two's complement representation of corr metric threshold , in dB with 3 bit precision after decimal point. i.e. upto 0.125dB accuracy. For example, 332 indicates -22.5dB threshold. 257 indicates -31.875dB threshold.
  0xFC S2LREG3 — WLAN ED S2L REG3
    [17:9] S2LDETTHRES2 — Contains two's complement representation of S2L corr metric threshold , in dB with 3 bit precision after decimal point. i.e. upto 0.125dB accuracy. For example, 332 indicates -22.5dB threshold. 257 indicates -31.875dB threshold.
    [8:0] S2LDETTHRES3 — Contains two's complement representation of S2L corr metric threshold , in dB with 3 bit precision after decimal point. i.e. upto 0.125dB accuracy. For example, 332 indicates -22.5dB threshold. 257 indicates -31.875dB threshold.
  0x100 AGCTOS2LCOUNTREG ro — WLAN ED AGC TO S2L COUNT REG
    [9:0] AGCTOS2LCOUNT — This register holds number of samples between AGC done and S2L success.
  0x104 CFOESTREALREG ro — WLAN ED CFO EST REAL REG
    [23:0] CFOESTREAL — This value holds the real part of the estimated CFO.
  0x108 CFOESTIMAGREG ro — WLAN ED CFO EST IMAG REG
    [23:0] CFOESTIMAG — This value holds the imaginary part of the estimated CFO.
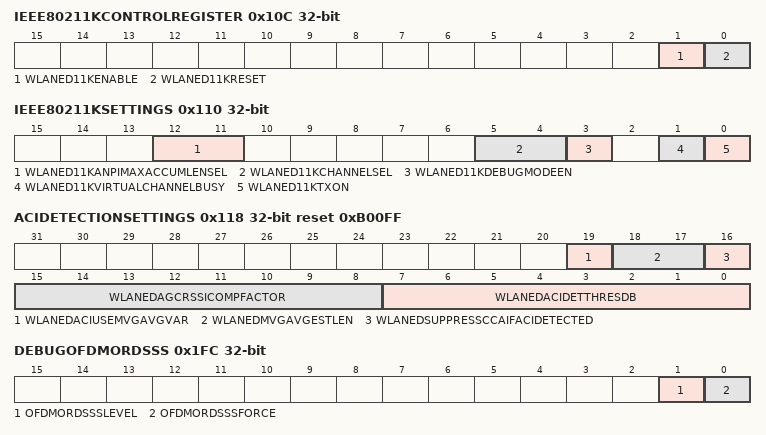
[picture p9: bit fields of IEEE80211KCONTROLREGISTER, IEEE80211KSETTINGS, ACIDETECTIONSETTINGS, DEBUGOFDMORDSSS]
  0x10C IEEE80211KCONTROLREGISTER — WLAN ED IEEE802 11K CONTROL REGISTER
    [1] WLANED11KENABLE — This flag when set to 1 Enables the Radio Measurement Module(11K standard support).
    [0] WLANED11KRESET — This flag when set to 1 Resets the Radio Measurement Module(11K standard support).
  0x110 IEEE80211KSETTINGS — WLAN ED IEEE802 11K SETTINGS
    [12:11] WLANED11KANPIMAXACCUMLENSEL — Select the maximum number of RSSI samples to be accumulated for ANPI measurement.'0' - maxAccumLen = 2^10;'1' - maxAccumLen = 2^15;'2' - maxAccumLen = 2^18;'3' - maxAccumLen = 2^20;After the maxAccumLen is reached, the accumulation is stopped and the values are retained.The module needs to be reset to do the accumulation again.
    [5:4] WLANED11KCHANNELSEL — This Flag selects the Bandwidth on which Radio Measurements should be done0 - 20MHz1 - 40MHz2 - 80MHz.
    [3] WLANED11KDEBUGMODEEN — This Flag when set to 1 (In Debug Mode) selects the system states TxOn and VirtualChannelBusy required for RadioMeasurementModule, from Register Memory instead of from Ports.
    [1] WLANED11KVIRTUALCHANNELBUSY
    [0] WLANED11KTXON
  0x118 ACIDETECTIONSETTINGS reset 0xB00FF — WLAN ED ACI DETECTION SETTINGS
    [19] WLANEDACIUSEMVGAVGVAR — This bit is used to choose between block averaged and moving averaged ED RSSI for ACI detection logic.Moving averaged ED variance improves the ED RSSI accuracy (reduces fluctuations).'1' - Use moving averaged based ED variance.'0' - Use normal block averaged ED variance.
    [18:17] WLANEDMVGAVGESTLEN — This specifies length of the moving averager (FIFO length) for averaging the ED variance. There is a ED variance estimation block that estimates prim20, prim40 and prim80 variances from the corresponding IQ samples. The variance estimates become valid once in a 0.8us interval (one symbol). The output of the variance estimator is then sent to a moving average FIFO for further averaging. The variance estimate is sampled on the valid and written to the FIFO. The length of moving average is specified as follows:
      0=Moving average fifo length is 1. Use the current ED variance. (So effective averaging is over 0.8us); 1=MovingAverageFifoLen1 (Moving average fifo length is 2. Average the latest two ED variances. (So effective averaging is over 1.6us)); 2=MovingAverageFifoLen2 (Moving average fifo length is 4. Average the latest four ED variances. (So effective averaging is over 3.2us)); 3=NotValid
    [16] WLANEDSUPPRESSCCAIFACIDETECTED — '1' - Enable ACI based CCA suppression, i. e. , if ACI is detected, then prim20, sec20, and sec40 CCA busy signals are forced to '0' during the duration.'0' - Disable. ACI detection does not have any impact on the CCA signal generation.
    [15:8] WLANEDAGCRSSICOMPFACTOR — This is an signed value in dB that used in the AGC RSSI computation, from the AGC log variance.AGC_RSSI= AGC_LOG_VARIANCE + AGC_RSSI_COMP_FACTOR - AGC_GAIN_DB
    [7:0] WLANEDACIDETTHRESDB — This threshold is in dB, Unsigned value. If the difference between AGC RSSI and ED RSSI is greater than this threshold, then ACI presence is detected, and hence ED Status assertion will be blocked. To bypass this feature, this threshold should be configured to 0xFF.
  0x11C AACIDETECTIONSETTINGS reset 0x1 — WLAN ED AACI DETECTION SETTINGS
    [0] WLANEDSUPPRESSCCAIFAACIDETECTED — '1' - Enable AACI based CCA suppression, i. e. if AACI is detected, then prim20, sec20, and sec40 CCA busy signals are forced to '0' for the duration.'0' - This feature is not active, i.e. AACI detection does not have any impact on the CCA signal generation.
  0x120 IEEE80211KANPIACCUMVALUE ro — WLAN ED IEEE802 11K ANPI ACCUM VALUE
    [23:0] WLANED11KANPIACCUMVALUE — This value holds the value of the current value of ANPI accumulator right shifted by 4.This is because ANPI accumulator is 28bit and register width is 24 bit.So when ANPI_DBM value is computed we need to do:ANPI_DBM = (ANPI_ACCUM_VALUE<<4) / ANPI_ACCUM_COUNT
  0x124 IEEE80211KANPIACCUMCOUNT ro — WLAN ED IEEE802 11K ANPI ACCUM COUNT
    [19:0] WLANED11KANPIACCUMCOUNT — This value holds the value of the current value of ANPI accumulator count.The count is incremented for everytime variance valid is generated.
  0x1FC DEBUGOFDMORDSSS — WLAN ED DEBUG OFDM OR DSSS
    [1] OFDMORDSSSLEVEL — Sets value of ed_ofdm_or_dsss signal when OFDM_OR_DSSS_FORCE is raised.
    [0] OFDMORDSSSFORCE — Enable debug mechanism for forcing ed_ofdm_or_dsss signal.
